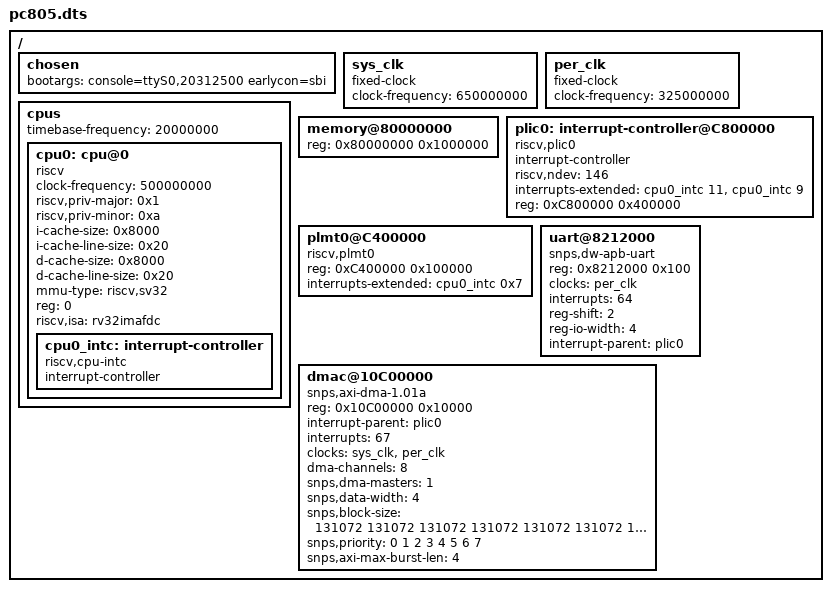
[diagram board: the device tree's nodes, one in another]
/dts-v1/;
/ {
	#address-cells = <1>;
	#size-cells = <1>;
	
	chosen {
        bootargs = "console=ttyS0,20312500 earlycon=sbi";
	};

	sys_clk: sys_clk {
		#clock-cells = <0>;
		compatible = "fixed-clock";
		clock-frequency = <650000000>;
	};

	per_clk: per_clk {
		#clock-cells = <0>;
		compatible = "fixed-clock";
		clock-frequency = <325000000>;
	};

	cpus {
		#address-cells = <1>;
		#size-cells = <0>;
		timebase-frequency = <20000000>;

		cpu0: cpu@0 {
			device_type = "cpu";
			compatible = "riscv";
			clock-frequency = <500000000>;
			riscv,priv-major = <0x1>;
			riscv,priv-minor = <0xa>;
			i-cache-size = <0x8000>;
			i-cache-line-size = <0x20>;
			d-cache-size = <0x8000>;
			d-cache-line-size = <0x20>;
			mmu-type = "riscv,sv32";
			reg = <0>;
			riscv,isa = "rv32imafdc";
			status = "okay";
			cpu0_intc: interrupt-controller {
				#interrupt-cells = <1>;
				compatible = "riscv,cpu-intc";
				interrupt-controller;
			};
		};
	};

	memory@80000000 {
		/* ddr 16M */
		device_type = "memory";
		reg = <0x80000000 0x1000000>;
	};


	plic0: interrupt-controller@C800000 {
		#interrupt-cells = <1>;
		compatible = "riscv,plic0";
		interrupt-controller;
		riscv,ndev = <146>;
		interrupts-extended =
			<&cpu0_intc 11 &cpu0_intc 9>;
		reg = <0xC800000 0x400000>;
	};

	plmt0@C400000 {
		compatible = "riscv,plmt0";
		reg = <0xC400000 0x100000>;
		interrupts-extended = <&cpu0_intc 0x7>;
	};

	uart@8212000 {
		compatible = "snps,dw-apb-uart";
		reg = <0x8212000 0x100>;
		/*clock-frequency = <325000000>;*/
		clocks = <&per_clk>;
		clock-names = "baudclk";
		interrupts = <64>;
		reg-shift = <2>;
		reg-io-width = <4>;
		interrupt-parent = <&plic0>;
	};

	dmac@10C00000 {
		compatible = "snps,axi-dma-1.01a";
		reg = <0x10C00000 0x10000>;
		interrupt-parent = <&plic0>;
		interrupts = <67>;
		clocks = <&sys_clk>, <&per_clk>;
		clock-names = "core-clk", "cfgr-clk";

		dma-channels = <8>;
		snps,dma-masters = <1>;
		snps,data-width = <4>;
		snps,block-size = <131072 131072 131072 131072 131072 131072 131072 131072>;
		snps,priority = <0 1 2 3 4 5 6 7>;
		snps,axi-max-burst-len = <4>;
	};
};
